# LM3S5Y36 register map
File version: 7944
Registers are 32-bit, read-write, no defined reset value unless marked. A register's access mark holds for its fields unless they carry their own. Offsets are from the block's base; [hi:lo] are bit positions; lines under a group give offsets from that group; {n}, {i} and the like mark numbered series.

## NVIC — Register map for NVIC peripheral
Base 0xE000E000; register names take the prefix NVIC
0x04 INT_TYPE — Interrupt Controller Type Reg
  [4:0] NVIC_INT_TYPE_LINES — Number of interrupt lines (x32)
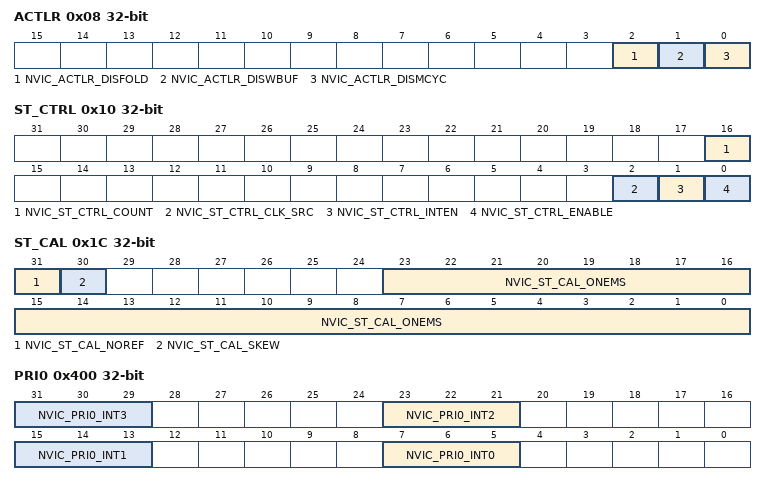
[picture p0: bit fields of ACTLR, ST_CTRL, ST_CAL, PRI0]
0x08 ACTLR — Auxiliary Control
  [2] NVIC_ACTLR_DISFOLD — Disable IT Folding
  [1] NVIC_ACTLR_DISWBUF — Disable Write Buffer
  [0] NVIC_ACTLR_DISMCYC — Disable Interrupts of Multiple Cycle Instructions
0x10 ST_CTRL — SysTick Control and Status Register
  [16] NVIC_ST_CTRL_COUNT — Count Flag
  [2] NVIC_ST_CTRL_CLK_SRC — Clock Source
  [1] NVIC_ST_CTRL_INTEN — Interrupt Enable
  [0] NVIC_ST_CTRL_ENABLE — Enable
0x14 ST_RELOAD — SysTick Reload Value Register
  [23:0] NVIC_ST_RELOAD — Reload Value
0x18 ST_CURRENT — SysTick Current Value Register
  [23:0] NVIC_ST_CURRENT — Current Value
0x1C ST_CAL — SysTick Calibration Value Reg
  [31] NVIC_ST_CAL_NOREF — No reference clock
  [30] NVIC_ST_CAL_SKEW — Clock skew
  [23:0] NVIC_ST_CAL_ONEMS — 1ms reference value
0x100 EN0 — Interrupt 0-31 Set Enable
  [31:0] NVIC_EN0_INT — Interrupt Enable
    1=Interrupt 0 enable; 2=Interrupt 1 enable; 4=Interrupt 2 enable; 8=Interrupt 3 enable; 16=Interrupt 4 enable; 32=Interrupt 5 enable; 64=Interrupt 6 enable; 128=Interrupt 7 enable; 0x100=Interrupt 8 enable; 0x200=Interrupt 9 enable; 0x400=Interrupt 10 enable; 0x800=Interrupt 11 enable; 0x1000=Interrupt 12 enable; 0x2000=Interrupt 13 enable; 0x4000=Interrupt 14 enable; 0x8000=Interrupt 15 enable; 0x10000=Interrupt 16 enable; 0x20000=Interrupt 17 enable; 0x40000=Interrupt 18 enable; 0x80000=Interrupt 19 enable; 0x100000=Interrupt 20 enable; 0x200000=Interrupt 21 enable; 0x400000=Interrupt 22 enable; 0x800000=Interrupt 23 enable; 0x1000000=Interrupt 24 enable; 0x2000000=Interrupt 25 enable; 0x4000000=Interrupt 26 enable; 0x8000000=Interrupt 27 enable; 0x10000000=Interrupt 28 enable; 0x20000000=Interrupt 29 enable; 0x40000000=Interrupt 30 enable; 0x80000000=Interrupt 31 enable
0x104 EN1 — Interrupt 32-54 Set Enable
  [22:0] NVIC_EN1_INT — Interrupt Enable
    1=Interrupt 32 enable; 2=Interrupt 33 enable; 4=Interrupt 34 enable; 8=Interrupt 35 enable; 16=Interrupt 36 enable; 32=Interrupt 37 enable; 64=Interrupt 38 enable; 128=Interrupt 39 enable; 0x100=Interrupt 40 enable; 0x200=Interrupt 41 enable; 0x400=Interrupt 42 enable; 0x800=Interrupt 43 enable; 0x1000=Interrupt 44 enable; 0x2000=Interrupt 45 enable; 0x4000=Interrupt 46 enable; 0x8000=Interrupt 47 enable; 0x10000=Interrupt 48 enable; 0x20000=Interrupt 49 enable; 0x40000=Interrupt 50 enable; 0x80000=Interrupt 51 enable; 0x100000=Interrupt 52 enable; 0x200000=Interrupt 53 enable; 0x400000=Interrupt 54 enable
0x180 DIS0 — Interrupt 0-31 Clear Enable
  [31:0] NVIC_DIS0_INT — Interrupt Disable
    1=Interrupt 0 disable; 2=Interrupt 1 disable; 4=Interrupt 2 disable; 8=Interrupt 3 disable; 16=Interrupt 4 disable; 32=Interrupt 5 disable; 64=Interrupt 6 disable; 128=Interrupt 7 disable; 0x100=Interrupt 8 disable; 0x200=Interrupt 9 disable; 0x400=Interrupt 10 disable; 0x800=Interrupt 11 disable; 0x1000=Interrupt 12 disable; 0x2000=Interrupt 13 disable; 0x4000=Interrupt 14 disable; 0x8000=Interrupt 15 disable; 0x10000=Interrupt 16 disable; 0x20000=Interrupt 17 disable; 0x40000=Interrupt 18 disable; 0x80000=Interrupt 19 disable; 0x100000=Interrupt 20 disable; 0x200000=Interrupt 21 disable; 0x400000=Interrupt 22 disable; 0x800000=Interrupt 23 disable; 0x1000000=Interrupt 24 disable; 0x2000000=Interrupt 25 disable; 0x4000000=Interrupt 26 disable; 0x8000000=Interrupt 27 disable; 0x10000000=Interrupt 28 disable; 0x20000000=Interrupt 29 disable; 0x40000000=Interrupt 30 disable; 0x80000000=Interrupt 31 disable
0x184 DIS1 — Interrupt 32-54 Clear Enable
  [22:0] NVIC_DIS1_INT — Interrupt Disable
    1=Interrupt 32 disable; 2=Interrupt 33 disable; 4=Interrupt 34 disable; 8=Interrupt 35 disable; 16=Interrupt 36 disable; 32=Interrupt 37 disable; 64=Interrupt 38 disable; 128=Interrupt 39 disable; 0x100=Interrupt 40 disable; 0x200=Interrupt 41 disable; 0x400=Interrupt 42 disable; 0x800=Interrupt 43 disable; 0x1000=Interrupt 44 disable; 0x2000=Interrupt 45 disable; 0x4000=Interrupt 46 disable; 0x8000=Interrupt 47 disable; 0x10000=Interrupt 48 disable; 0x20000=Interrupt 49 disable; 0x40000=Interrupt 50 disable; 0x80000=Interrupt 51 disable; 0x100000=Interrupt 52 disable; 0x200000=Interrupt 53 disable; 0x400000=Interrupt 54 disable
0x200 PEND0 — Interrupt 0-31 Set Pending
  [31:0] NVIC_PEND0_INT — Interrupt Set Pending
    1=Interrupt 0 pend; 2=Interrupt 1 pend; 4=Interrupt 2 pend; 8=Interrupt 3 pend; 16=Interrupt 4 pend; 32=Interrupt 5 pend; 64=Interrupt 6 pend; 128=Interrupt 7 pend; 0x100=Interrupt 8 pend; 0x200=Interrupt 9 pend; 0x400=Interrupt 10 pend; 0x800=Interrupt 11 pend; 0x1000=Interrupt 12 pend; 0x2000=Interrupt 13 pend; 0x4000=Interrupt 14 pend; 0x8000=Interrupt 15 pend; 0x10000=Interrupt 16 pend; 0x20000=Interrupt 17 pend; 0x40000=Interrupt 18 pend; 0x80000=Interrupt 19 pend; 0x100000=Interrupt 20 pend; 0x200000=Interrupt 21 pend; 0x400000=Interrupt 22 pend; 0x800000=Interrupt 23 pend; 0x1000000=Interrupt 24 pend; 0x2000000=Interrupt 25 pend; 0x4000000=Interrupt 26 pend; 0x8000000=Interrupt 27 pend; 0x10000000=Interrupt 28 pend; 0x20000000=Interrupt 29 pend; 0x40000000=Interrupt 30 pend; 0x80000000=Interrupt 31 pend
0x204 PEND1 — Interrupt 32-54 Set Pending
  [22:0] NVIC_PEND1_INT — Interrupt Set Pending
    1=Interrupt 32 pend; 2=Interrupt 33 pend; 4=Interrupt 34 pend; 8=Interrupt 35 pend; 16=Interrupt 36 pend; 32=Interrupt 37 pend; 64=Interrupt 38 pend; 128=Interrupt 39 pend; 0x100=Interrupt 40 pend; 0x200=Interrupt 41 pend; 0x400=Interrupt 42 pend; 0x800=Interrupt 43 pend; 0x1000=Interrupt 44 pend; 0x2000=Interrupt 45 pend; 0x4000=Interrupt 46 pend; 0x8000=Interrupt 47 pend; 0x10000=Interrupt 48 pend; 0x20000=Interrupt 49 pend; 0x40000=Interrupt 50 pend; 0x80000=Interrupt 51 pend; 0x100000=Interrupt 52 pend; 0x200000=Interrupt 53 pend; 0x400000=Interrupt 54 pend
0x280 UNPEND0 — Interrupt 0-31 Clear Pending
  [31:0] NVIC_UNPEND0_INT — Interrupt Clear Pending
    1=Interrupt 0 unpend; 2=Interrupt 1 unpend; 4=Interrupt 2 unpend; 8=Interrupt 3 unpend; 16=Interrupt 4 unpend; 32=Interrupt 5 unpend; 64=Interrupt 6 unpend; 128=Interrupt 7 unpend; 0x100=Interrupt 8 unpend; 0x200=Interrupt 9 unpend; 0x400=Interrupt 10 unpend; 0x800=Interrupt 11 unpend; 0x1000=Interrupt 12 unpend; 0x2000=Interrupt 13 unpend; 0x4000=Interrupt 14 unpend; 0x8000=Interrupt 15 unpend; 0x10000=Interrupt 16 unpend; 0x20000=Interrupt 17 unpend; 0x40000=Interrupt 18 unpend; 0x80000=Interrupt 19 unpend; 0x100000=Interrupt 20 unpend; 0x200000=Interrupt 21 unpend; 0x400000=Interrupt 22 unpend; 0x800000=Interrupt 23 unpend; 0x1000000=Interrupt 24 unpend; 0x2000000=Interrupt 25 unpend; 0x4000000=Interrupt 26 unpend; 0x8000000=Interrupt 27 unpend; 0x10000000=Interrupt 28 unpend; 0x20000000=Interrupt 29 unpend; 0x40000000=Interrupt 30 unpend; 0x80000000=Interrupt 31 unpend
0x284 UNPEND1 — Interrupt 32-54 Clear Pending
  [22:0] NVIC_UNPEND1_INT — Interrupt Clear Pending
    1=Interrupt 32 unpend; 2=Interrupt 33 unpend; 4=Interrupt 34 unpend; 8=Interrupt 35 unpend; 16=Interrupt 36 unpend; 32=Interrupt 37 unpend; 64=Interrupt 38 unpend; 128=Interrupt 39 unpend; 0x100=Interrupt 40 unpend; 0x200=Interrupt 41 unpend; 0x400=Interrupt 42 unpend; 0x800=Interrupt 43 unpend; 0x1000=Interrupt 44 unpend; 0x2000=Interrupt 45 unpend; 0x4000=Interrupt 46 unpend; 0x8000=Interrupt 47 unpend; 0x10000=Interrupt 48 unpend; 0x20000=Interrupt 49 unpend; 0x40000=Interrupt 50 unpend; 0x80000=Interrupt 51 unpend; 0x100000=Interrupt 52 unpend; 0x200000=Interrupt 53 unpend; 0x400000=Interrupt 54 unpend
0x300 ACTIVE0 — Interrupt 0-31 Active Bit
  [31:0] NVIC_ACTIVE0_INT — Interrupt Active
    1=Interrupt 0 active; 2=Interrupt 1 active; 4=Interrupt 2 active; 8=Interrupt 3 active; 16=Interrupt 4 active; 32=Interrupt 5 active; 64=Interrupt 6 active; 128=Interrupt 7 active; 0x100=Interrupt 8 active; 0x200=Interrupt 9 active; 0x400=Interrupt 10 active; 0x800=Interrupt 11 active; 0x1000=Interrupt 12 active; 0x2000=Interrupt 13 active; 0x4000=Interrupt 14 active; 0x8000=Interrupt 15 active; 0x10000=Interrupt 16 active; 0x20000=Interrupt 17 active; 0x40000=Interrupt 18 active; 0x80000=Interrupt 19 active; 0x100000=Interrupt 20 active; 0x200000=Interrupt 21 active; 0x400000=Interrupt 22 active; 0x800000=Interrupt 23 active; 0x1000000=Interrupt 24 active; 0x2000000=Interrupt 25 active; 0x4000000=Interrupt 26 active; 0x8000000=Interrupt 27 active; 0x10000000=Interrupt 28 active; 0x20000000=Interrupt 29 active; 0x40000000=Interrupt 30 active; 0x80000000=Interrupt 31 active
0x304 ACTIVE1 — Interrupt 32-54 Active Bit
  [22:0] NVIC_ACTIVE1_INT — Interrupt Active
    1=Interrupt 32 active; 2=Interrupt 33 active; 4=Interrupt 34 active; 8=Interrupt 35 active; 16=Interrupt 36 active; 32=Interrupt 37 active; 64=Interrupt 38 active; 128=Interrupt 39 active; 0x100=Interrupt 40 active; 0x200=Interrupt 41 active; 0x400=Interrupt 42 active; 0x800=Interrupt 43 active; 0x1000=Interrupt 44 active; 0x2000=Interrupt 45 active; 0x4000=Interrupt 46 active; 0x8000=Interrupt 47 active; 0x10000=Interrupt 48 active; 0x20000=Interrupt 49 active; 0x40000=Interrupt 50 active; 0x80000=Interrupt 51 active; 0x100000=Interrupt 52 active; 0x200000=Interrupt 53 active; 0x400000=Interrupt 54 active
0x400 PRI0 — Interrupt 0-3 Priority
  [8n+7:8n+5] NVIC_PRI0_INT{n} (n=0..3) — Interrupt {n} Priority Mask
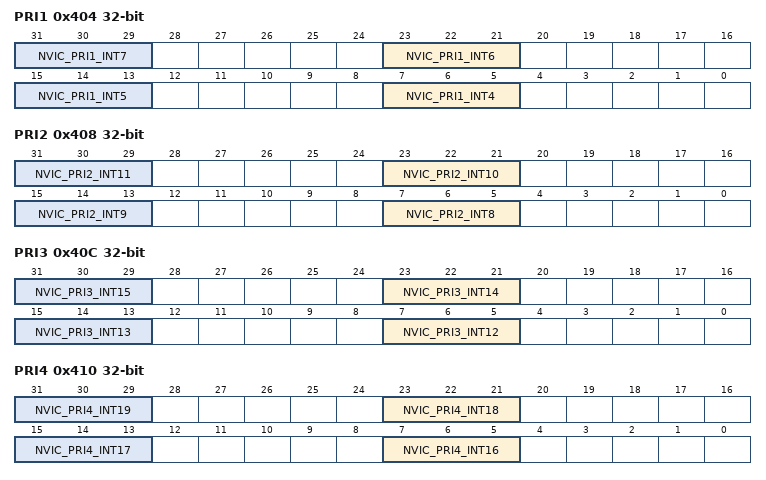
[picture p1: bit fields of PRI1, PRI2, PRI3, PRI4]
0x404 PRI1 — Interrupt 4-7 Priority
  [8n-25:8n-27] NVIC_PRI1_INT{n} (n=4..7) — Interrupt {n} Priority Mask
0x408 PRI2 — Interrupt 8-11 Priority
  [8n-57:8n-59] NVIC_PRI2_INT{n} (n=8..11) — Interrupt {n} Priority Mask
0x40C PRI3 — Interrupt 12-15 Priority
  [8n-89:8n-91] NVIC_PRI3_INT{n} (n=12..15) — Interrupt {n} Priority Mask
0x410 PRI4 — Interrupt 16-19 Priority
  [8n-121:8n-123] NVIC_PRI4_INT{n} (n=16..19) — Interrupt {n} Priority Mask
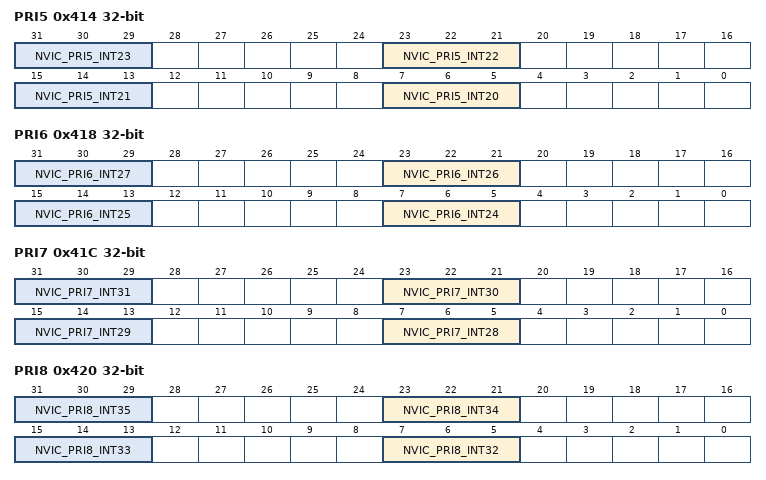
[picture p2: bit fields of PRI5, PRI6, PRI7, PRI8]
0x414 PRI5 — Interrupt 20-23 Priority
  [8n-153:8n-155] NVIC_PRI5_INT{n} (n=20..23) — Interrupt {n} Priority Mask
0x418 PRI6 — Interrupt 24-27 Priority
  [8n-185:8n-187] NVIC_PRI6_INT{n} (n=24..27) — Interrupt {n} Priority Mask
0x41C PRI7 — Interrupt 28-31 Priority
  [8n-217:8n-219] NVIC_PRI7_INT{n} (n=28..31) — Interrupt {n} Priority Mask
0x420 PRI8 — Interrupt 32-35 Priority
  [8n-249:8n-251] NVIC_PRI8_INT{n} (n=32..35) — Interrupt {n} Priority Mask
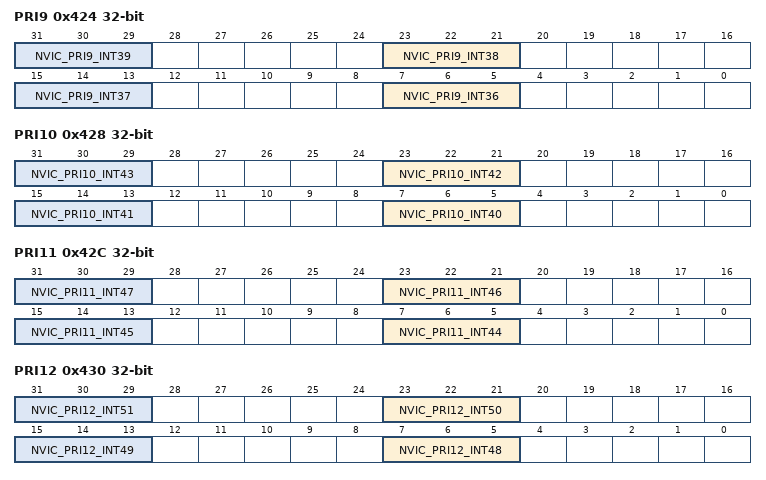
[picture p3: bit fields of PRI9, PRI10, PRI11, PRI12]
0x424 PRI9 — Interrupt 36-39 Priority
  [8n-281:8n-283] NVIC_PRI9_INT{n} (n=36..39) — Interrupt {n} Priority Mask
0x428 PRI10 — Interrupt 40-43 Priority
  [8n-313:8n-315] NVIC_PRI10_INT{n} (n=40..43) — Interrupt {n} Priority Mask
0x42C PRI11 — Interrupt 44-47 Priority
  [8n-345:8n-347] NVIC_PRI11_INT{n} (n=44..47) — Interrupt {n} Priority Mask
0x430 PRI12 — Interrupt 48-51 Priority
  [8n-377:8n-379] NVIC_PRI12_INT{n} (n=48..51) — Interrupt {n} Priority Mask
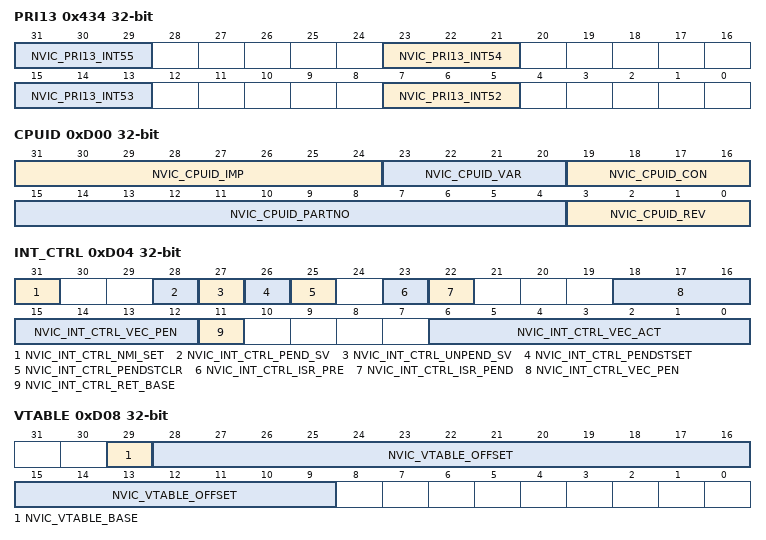
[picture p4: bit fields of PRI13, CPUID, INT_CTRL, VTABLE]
0x434 PRI13 — Interrupt 52-53 Priority
  [8n-409:8n-411] NVIC_PRI13_INT{n} (n=52..55) — Interrupt {n} Priority Mask
0xD00 CPUID — CPU ID Base
  [31:24] NVIC_CPUID_IMP — Implementer Code
    65=NVIC_CPUID_IMP_ARM (ARM)
  [23:20] NVIC_CPUID_VAR — Variant Number
  [19:16] NVIC_CPUID_CON — Constant
  [15:4] NVIC_CPUID_PARTNO — Part Number
    0xC23=NVIC_CPUID_PARTNO_CM3 (Cortex-M3 processor)
  [3:0] NVIC_CPUID_REV — Revision Number
0xD04 INT_CTRL — Interrupt Control and State
  [31] NVIC_INT_CTRL_NMI_SET — NMI Set Pending
  [28] NVIC_INT_CTRL_PEND_SV — PendSV Set Pending
  [27] NVIC_INT_CTRL_UNPEND_SV — PendSV Clear Pending
  [26] NVIC_INT_CTRL_PENDSTSET — SysTick Set Pending
  [25] NVIC_INT_CTRL_PENDSTCLR — SysTick Clear Pending
  [23] NVIC_INT_CTRL_ISR_PRE — Debug Interrupt Handling
  [22] NVIC_INT_CTRL_ISR_PEND — Interrupt Pending
  [18:12] NVIC_INT_CTRL_VEC_PEN — Interrupt Pending Vector Number
    2=NVIC_INT_CTRL_VEC_PEN_NMI (NMI); 3=NVIC_INT_CTRL_VEC_PEN_HARD (Hard fault); 4=NVIC_INT_CTRL_VEC_PEN_MEM (Memory management fault); 5=NVIC_INT_CTRL_VEC_PEN_BUS (Bus fault); 6=NVIC_INT_CTRL_VEC_PEN_USG (Usage fault); 11=NVIC_INT_CTRL_VEC_PEN_SVC (SVCall); 14=NVIC_INT_CTRL_VEC_PEN_PNDSV (PendSV); 15=NVIC_INT_CTRL_VEC_PEN_TICK (SysTick)
  [11] NVIC_INT_CTRL_RET_BASE — Return to Base
  [6:0] NVIC_INT_CTRL_VEC_ACT — Interrupt Pending Vector Number
0xD08 VTABLE — Vector Table Offset
  [29] NVIC_VTABLE_BASE — Vector Table Base
  [28:9] NVIC_VTABLE_OFFSET — Vector Table Offset
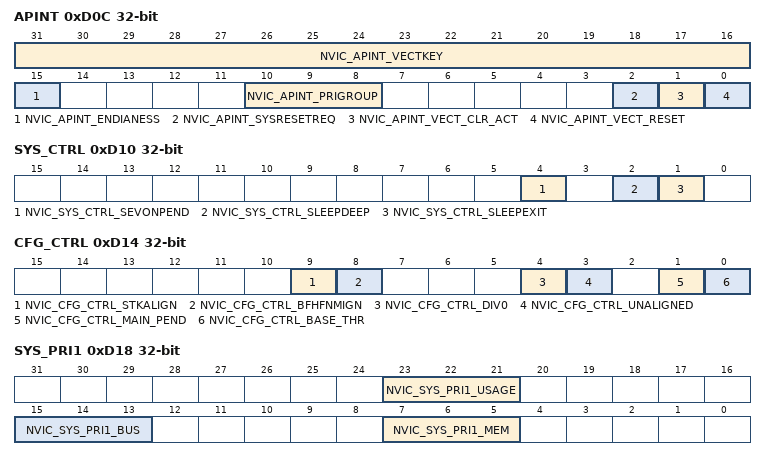
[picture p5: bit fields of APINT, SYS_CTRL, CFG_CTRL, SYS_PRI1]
0xD0C APINT — Application Interrupt and Reset Control
  [31:16] NVIC_APINT_VECTKEY — Register Key
    0x5FA=NVIC_APINT_VECTKEY (Vector key)
  [15] NVIC_APINT_ENDIANESS — Data Endianess
  [10:8] NVIC_APINT_PRIGROUP — Interrupt Priority Grouping
    0=NVIC_APINT_PRIGROUP_7_1 (Priority group 7.1 split); 1=NVIC_APINT_PRIGROUP_6_2 (Priority group 6.2 split); 2=NVIC_APINT_PRIGROUP_5_3 (Priority group 5.3 split); 3=NVIC_APINT_PRIGROUP_4_4 (Priority group 4.4 split); 4=NVIC_APINT_PRIGROUP_3_5 (Priority group 3.5 split); 5=NVIC_APINT_PRIGROUP_2_6 (Priority group 2.6 split); 6=NVIC_APINT_PRIGROUP_1_7 (Priority group 1.7 split); 7=NVIC_APINT_PRIGROUP_0_8 (Priority group 0.8 split)
  [2] NVIC_APINT_SYSRESETREQ — System Reset Request
  [1] NVIC_APINT_VECT_CLR_ACT — Clear Active NMI / Fault
  [0] NVIC_APINT_VECT_RESET — System Reset
0xD10 SYS_CTRL — System Control
  [4] NVIC_SYS_CTRL_SEVONPEND — Wake Up on Pending
  [2] NVIC_SYS_CTRL_SLEEPDEEP — Deep Sleep Enable
  [1] NVIC_SYS_CTRL_SLEEPEXIT — Sleep on ISR Exit
0xD14 CFG_CTRL — Configuration and Control
  [9] NVIC_CFG_CTRL_STKALIGN — Stack Alignment on Exception Entry
  [8] NVIC_CFG_CTRL_BFHFNMIGN — Ignore Bus Fault in NMI and Fault
  [4] NVIC_CFG_CTRL_DIV0 — Trap on Divide by 0
  [3] NVIC_CFG_CTRL_UNALIGNED — Trap on Unaligned Access
  [1] NVIC_CFG_CTRL_MAIN_PEND — Allow Main Interrupt Trigger
  [0] NVIC_CFG_CTRL_BASE_THR — Thread State Control
0xD18 SYS_PRI1 — System Handler Priority 1
  [23:21] NVIC_SYS_PRI1_USAGE — Usage Fault Priority
  [15:13] NVIC_SYS_PRI1_BUS — Bus Fault Priority
  [7:5] NVIC_SYS_PRI1_MEM — Memory Management Fault Priority
0xD1C SYS_PRI2 — System Handler Priority 2
  [31:29] NVIC_SYS_PRI2_SVC — SVCall Priority
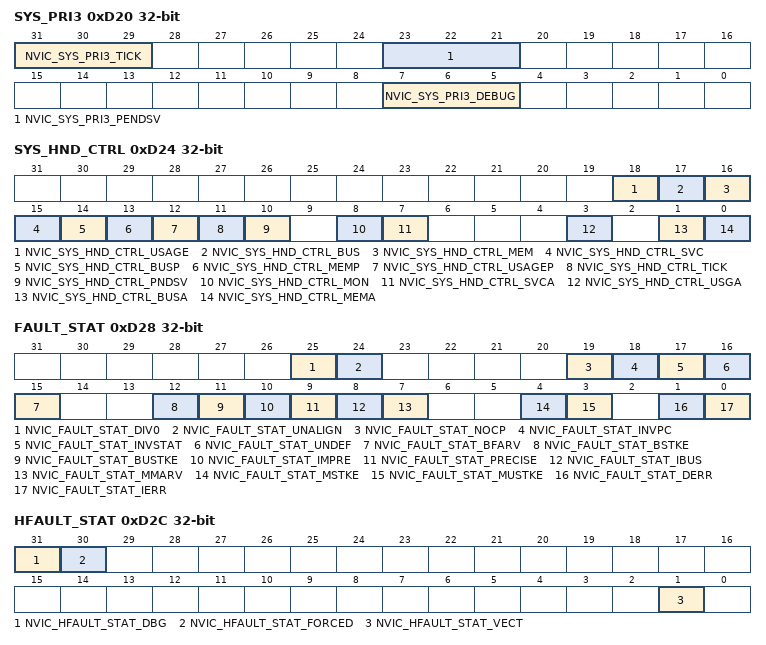
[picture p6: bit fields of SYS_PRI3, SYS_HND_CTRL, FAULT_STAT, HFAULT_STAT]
0xD20 SYS_PRI3 — System Handler Priority 3
  [31:29] NVIC_SYS_PRI3_TICK — SysTick Exception Priority
  [23:21] NVIC_SYS_PRI3_PENDSV — PendSV Priority
  [7:5] NVIC_SYS_PRI3_DEBUG — Debug Priority
0xD24 SYS_HND_CTRL — System Handler Control and State
  [18] NVIC_SYS_HND_CTRL_USAGE — Usage Fault Enable
  [17] NVIC_SYS_HND_CTRL_BUS — Bus Fault Enable
  [16] NVIC_SYS_HND_CTRL_MEM — Memory Management Fault Enable
  [15] NVIC_SYS_HND_CTRL_SVC — SVC Call Pending
  [14] NVIC_SYS_HND_CTRL_BUSP — Bus Fault Pending
  [13] NVIC_SYS_HND_CTRL_MEMP — Memory Management Fault Pending
  [12] NVIC_SYS_HND_CTRL_USAGEP — Usage Fault Pending
  [11] NVIC_SYS_HND_CTRL_TICK — SysTick Exception Active
  [10] NVIC_SYS_HND_CTRL_PNDSV — PendSV Exception Active
  [8] NVIC_SYS_HND_CTRL_MON — Debug Monitor Active
  [7] NVIC_SYS_HND_CTRL_SVCA — SVC Call Active
  [3] NVIC_SYS_HND_CTRL_USGA — Usage Fault Active
  [1] NVIC_SYS_HND_CTRL_BUSA — Bus Fault Active
  [0] NVIC_SYS_HND_CTRL_MEMA — Memory Management Fault Active
0xD28 FAULT_STAT — Configurable Fault Status
  [25] NVIC_FAULT_STAT_DIV0 — Divide-by-Zero Usage Fault
  [24] NVIC_FAULT_STAT_UNALIGN — Unaligned Access Usage Fault
  [19] NVIC_FAULT_STAT_NOCP — No Coprocessor Usage Fault
  [18] NVIC_FAULT_STAT_INVPC — Invalid PC Load Usage Fault
  [17] NVIC_FAULT_STAT_INVSTAT — Invalid State Usage Fault
  [16] NVIC_FAULT_STAT_UNDEF — Undefined Instruction Usage Fault
  [15] NVIC_FAULT_STAT_BFARV — Bus Fault Address Register Valid
  [12] NVIC_FAULT_STAT_BSTKE — Stack Bus Fault
  [11] NVIC_FAULT_STAT_BUSTKE — Unstack Bus Fault
  [10] NVIC_FAULT_STAT_IMPRE — Imprecise Data Bus Error
  [9] NVIC_FAULT_STAT_PRECISE — Precise Data Bus Error
  [8] NVIC_FAULT_STAT_IBUS — Instruction Bus Error
  [7] NVIC_FAULT_STAT_MMARV — Memory Management Fault Address Register Valid
  [4] NVIC_FAULT_STAT_MSTKE — Stack Access Violation
  [3] NVIC_FAULT_STAT_MUSTKE — Unstack Access Violation
  [1] NVIC_FAULT_STAT_DERR — Data Access Violation
  [0] NVIC_FAULT_STAT_IERR — Instruction Access Violation
0xD2C HFAULT_STAT — Hard Fault Status
  [31] NVIC_HFAULT_STAT_DBG — Debug Event
  [30] NVIC_HFAULT_STAT_FORCED — Forced Hard Fault
  [1] NVIC_HFAULT_STAT_VECT — Vector Table Read Fault
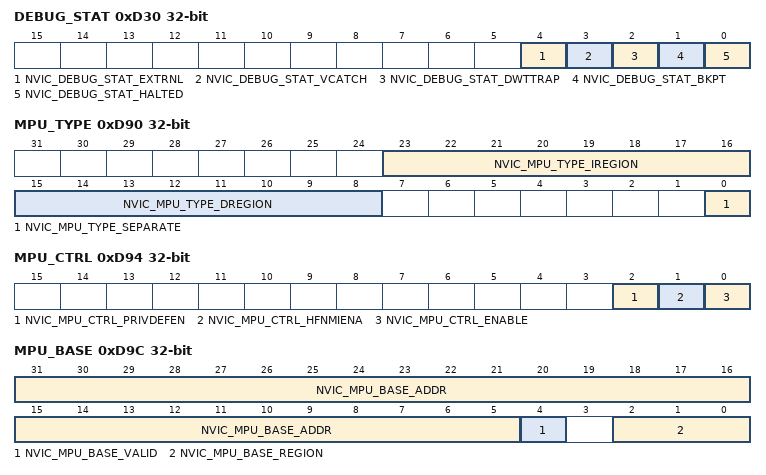
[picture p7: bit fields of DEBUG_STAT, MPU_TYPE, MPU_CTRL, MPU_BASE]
0xD30 DEBUG_STAT — Debug Status Register
  [4] NVIC_DEBUG_STAT_EXTRNL — EDBGRQ asserted
  [3] NVIC_DEBUG_STAT_VCATCH — Vector catch
  [2] NVIC_DEBUG_STAT_DWTTRAP — DWT match
  [1] NVIC_DEBUG_STAT_BKPT — Breakpoint instruction
  [0] NVIC_DEBUG_STAT_HALTED — Halt request
0xD34 MM_ADDR — Memory Management Fault Address
  [31:0] NVIC_MM_ADDR — Fault Address
0xD38 FAULT_ADDR — Bus Fault Address
  [31:0] NVIC_FAULT_ADDR — Fault Address
0xD90 MPU_TYPE
  [23:16] NVIC_MPU_TYPE_IREGION — Number of I Regions
  [15:8] NVIC_MPU_TYPE_DREGION — Number of D Regions
  [0] NVIC_MPU_TYPE_SEPARATE — Separate or Unified MPU
0xD94 MPU_CTRL — MPU Control
  [2] NVIC_MPU_CTRL_PRIVDEFEN — MPU Default Region
  [1] NVIC_MPU_CTRL_HFNMIENA — MPU Enabled During Faults
  [0] NVIC_MPU_CTRL_ENABLE — MPU Enable
0xD98 MPU_NUMBER — MPU Region Number
  [2:0] NVIC_MPU_NUMBER — MPU Region to Access
0xD9C MPU_BASE — MPU Region Base Address
  [31:5] NVIC_MPU_BASE_ADDR — Base Address Mask
  [4] NVIC_MPU_BASE_VALID — Region Number Valid
  [2:0] NVIC_MPU_BASE_REGION — Region Number
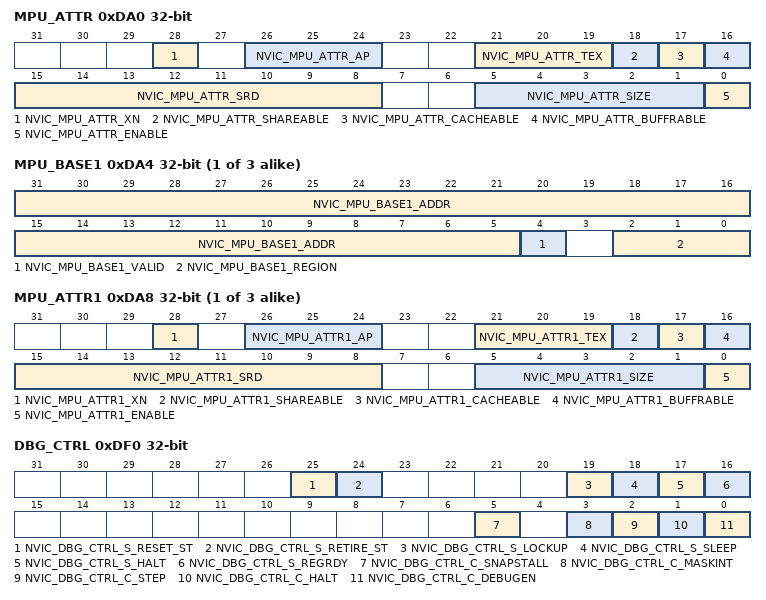
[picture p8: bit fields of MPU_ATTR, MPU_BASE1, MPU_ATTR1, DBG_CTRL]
0xDA0 MPU_ATTR — MPU Region Attribute and Size
  [28] NVIC_MPU_ATTR_XN — Instruction Access Disable
  [26:24] NVIC_MPU_ATTR_AP — Access Privilege
    0=NVIC_MPU_ATTR_AP_NO_NO (prv: no access, usr: no access); 1=NVIC_MPU_ATTR_AP_RW_NO (prv: rw, usr: none); 2=NVIC_MPU_ATTR_AP_RW_RO (prv: rw, usr: read-only); 3=NVIC_MPU_ATTR_AP_RW_RW (prv: rw, usr: rw); 5=NVIC_MPU_ATTR_AP_RO_NO (prv: ro, usr: none); 6=NVIC_MPU_ATTR_AP_RO_RO (prv: ro, usr: ro)
  [21:19] NVIC_MPU_ATTR_TEX — Type Extension Mask
  [18] NVIC_MPU_ATTR_SHAREABLE — Shareable
  [17] NVIC_MPU_ATTR_CACHEABLE — Cacheable
  [16] NVIC_MPU_ATTR_BUFFRABLE — Bufferable
  [15:8] NVIC_MPU_ATTR_SRD — Subregion Disable Bits
    1=Sub-region 0 disable; 2=Sub-region 1 disable; 4=Sub-region 2 disable; 8=Sub-region 3 disable; 16=Sub-region 4 disable; 32=Sub-region 5 disable; 64=Sub-region 6 disable; 128=Sub-region 7 disable
  [5:1] NVIC_MPU_ATTR_SIZE — Region Size Mask
    4=NVIC_MPU_ATTR_SIZE_32B (Region size 32 bytes); 5=NVIC_MPU_ATTR_SIZE_64B (Region size 64 bytes); 6=NVIC_MPU_ATTR_SIZE_128B (Region size 128 bytes); 7=NVIC_MPU_ATTR_SIZE_256B (Region size 256 bytes); 8=NVIC_MPU_ATTR_SIZE_512B (Region size 512 bytes); 9=NVIC_MPU_ATTR_SIZE_1K (Region size 1 Kbytes); 10=NVIC_MPU_ATTR_SIZE_2K (Region size 2 Kbytes); 11=NVIC_MPU_ATTR_SIZE_4K (Region size 4 Kbytes); 12=NVIC_MPU_ATTR_SIZE_8K (Region size 8 Kbytes); 13=NVIC_MPU_ATTR_SIZE_16K (Region size 16 Kbytes); 14=NVIC_MPU_ATTR_SIZE_32K (Region size 32 Kbytes); 15=NVIC_MPU_ATTR_SIZE_64K (Region size 64 Kbytes); 16=NVIC_MPU_ATTR_SIZE_128K (Region size 128 Kbytes); 17=NVIC_MPU_ATTR_SIZE_256K (Region size 256 Kbytes); 18=NVIC_MPU_ATTR_SIZE_512K (Region size 512 Kbytes); 19=NVIC_MPU_ATTR_SIZE_1M (Region size 1 Mbytes); 20=NVIC_MPU_ATTR_SIZE_2M (Region size 2 Mbytes); 21=NVIC_MPU_ATTR_SIZE_4M (Region size 4 Mbytes); 22=NVIC_MPU_ATTR_SIZE_8M (Region size 8 Mbytes); 23=NVIC_MPU_ATTR_SIZE_16M (Region size 16 Mbytes); 24=NVIC_MPU_ATTR_SIZE_32M (Region size 32 Mbytes); 25=NVIC_MPU_ATTR_SIZE_64M (Region size 64 Mbytes); 26=NVIC_MPU_ATTR_SIZE_128M (Region size 128 Mbytes); 27=NVIC_MPU_ATTR_SIZE_256M (Region size 256 Mbytes); 28=NVIC_MPU_ATTR_SIZE_512M (Region size 512 Mbytes); 29=NVIC_MPU_ATTR_SIZE_1G (Region size 1 Gbytes); 30=NVIC_MPU_ATTR_SIZE_2G (Region size 2 Gbytes); 31=NVIC_MPU_ATTR_SIZE_4G (Region size 4 Gbytes)
  [0] NVIC_MPU_ATTR_ENABLE — Region Enable
{0xD9C+8i} MPU_BASE{i} (i=1..3) — MPU Region Base Address Alias {i}
  [31:5] NVIC_MPU_BASE{i}_ADDR — Base Address Mask
  [4] NVIC_MPU_BASE{i}_VALID — Region Number Valid
  [2:0] NVIC_MPU_BASE{i}_REGION — Region Number
{0xDA0+8i} MPU_ATTR{i} (i=1..3) — MPU Region Attribute and Size Alias {i}
  [28] NVIC_MPU_ATTR{i}_XN — Instruction Access Disable
  [26:24] NVIC_MPU_ATTR{i}_AP — Access Privilege
  [21:19] NVIC_MPU_ATTR{i}_TEX — Type Extension Mask
  [18] NVIC_MPU_ATTR{i}_SHAREABLE — Shareable
  [17] NVIC_MPU_ATTR{i}_CACHEABLE — Cacheable
  [16] NVIC_MPU_ATTR{i}_BUFFRABLE — Bufferable
  [15:8] NVIC_MPU_ATTR{i}_SRD — Subregion Disable Bits
  [5:1] NVIC_MPU_ATTR{i}_SIZE — Region Size Mask
  [0] NVIC_MPU_ATTR{i}_ENABLE — Region Enable
0xDF0 DBG_CTRL — Debug Control and Status Reg
  [25] NVIC_DBG_CTRL_S_RESET_ST — Core has reset since last read
  [24] NVIC_DBG_CTRL_S_RETIRE_ST — Core has executed insruction since last read
  [19] NVIC_DBG_CTRL_S_LOCKUP — Core is locked up
  [18] NVIC_DBG_CTRL_S_SLEEP — Core is sleeping
  [17] NVIC_DBG_CTRL_S_HALT — Core status on halt
  [16] NVIC_DBG_CTRL_S_REGRDY — Register read/write available
  [5] NVIC_DBG_CTRL_C_SNAPSTALL — Breaks a stalled load/store
  [3] NVIC_DBG_CTRL_C_MASKINT — Mask interrupts when stepping
  [2] NVIC_DBG_CTRL_C_STEP — Step the core
  [1] NVIC_DBG_CTRL_C_HALT — Halt the core
  [0] NVIC_DBG_CTRL_C_DEBUGEN — Enable debug
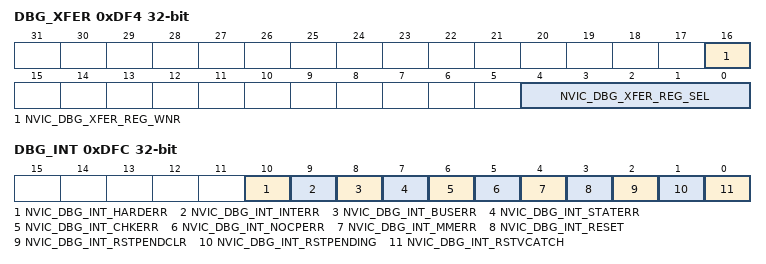
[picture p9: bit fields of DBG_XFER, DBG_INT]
0xDF4 DBG_XFER — Debug Core Reg. Transfer Select
  [16] NVIC_DBG_XFER_REG_WNR — Write or not read
  [4:0] NVIC_DBG_XFER_REG_SEL — Register
    {v}=NVIC_DBG_XFER_REG_R{v} (Register R{v}) (v=0..15); 16=NVIC_DBG_XFER_REG_FLAGS (xPSR/Flags register); 17=NVIC_DBG_XFER_REG_MSP (Main SP); 18=NVIC_DBG_XFER_REG_PSP (Process SP); 19=NVIC_DBG_XFER_REG_DSP (Deep SP); 20=NVIC_DBG_XFER_REG_CFBP (Control/Fault/BasePri/PriMask)
0xDF8 DBG_DATA — Debug Core Register Data
  [31:0] NVIC_DBG_DATA — Data temporary cache
0xDFC DBG_INT — Debug Reset Interrupt Control
  [10] NVIC_DBG_INT_HARDERR — Debug trap on hard fault
  [9] NVIC_DBG_INT_INTERR — Debug trap on interrupt errors
  [8] NVIC_DBG_INT_BUSERR — Debug trap on bus error
  [7] NVIC_DBG_INT_STATERR — Debug trap on usage fault state
  [6] NVIC_DBG_INT_CHKERR — Debug trap on usage fault check
  [5] NVIC_DBG_INT_NOCPERR — Debug trap on coprocessor error
  [4] NVIC_DBG_INT_MMERR — Debug trap on mem manage fault
  [3] NVIC_DBG_INT_RESET — Core reset status
  [2] NVIC_DBG_INT_RSTPENDCLR — Clear pending core reset
  [1] NVIC_DBG_INT_RSTPENDING — Core reset is pending
  [0] NVIC_DBG_INT_RSTVCATCH — Reset vector catch
0xF00 SW_TRIG wo — Software Trigger Interrupt
  [5:0] NVIC_SW_TRIG_INTID — Interrupt ID
